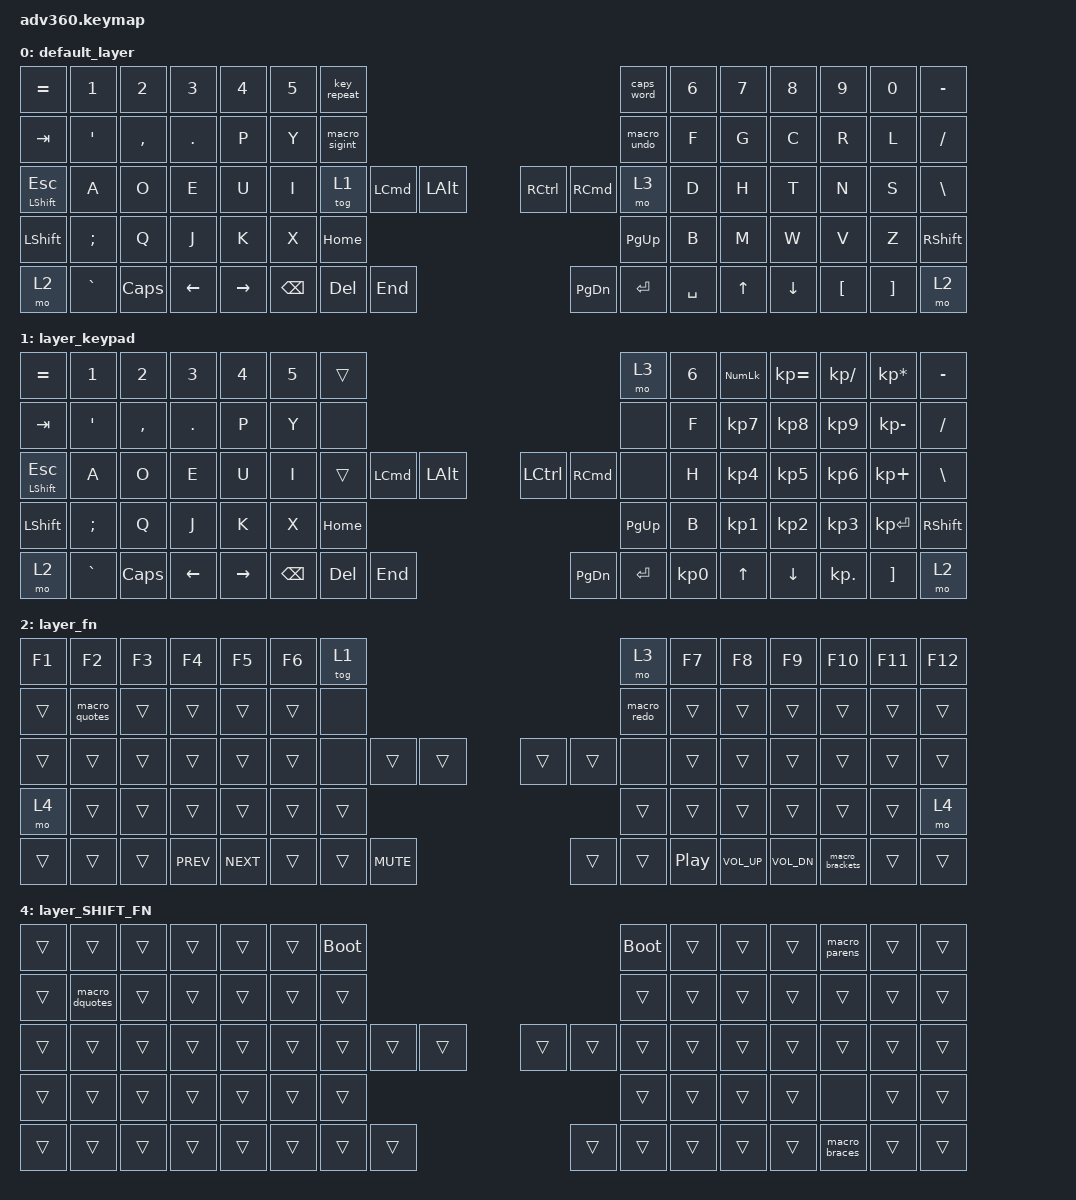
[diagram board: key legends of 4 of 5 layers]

/*
 * Copyright (c) 2020 The ZMK Contributors
 *
 * SPDX-License-Identifier: MIT
 */


/* THIS FILE WAS GENERATED!
 *
 * This file was generated automatically. You may or may not want to
 * edit it directly.
 */

#include <behaviors.dtsi>
#include <dt-bindings/zmk/keys.h>
#include <dt-bindings/zmk/bt.h>
#include <dt-bindings/zmk/rgb.h>
#include <dt-bindings/zmk/backlight.h>

/ {
  behaviors {
    #include "macros.dtsi"

    hm: homerow_mods {
        compatible = "zmk,behavior-hold-tap";
        label = "HOMEROW_MODS";
        #binding-cells = <2>;
        tapping-term-ms = <200>;
        quick_tap_ms = <175>;
        flavor = "tap-preferred";
        bindings = <&kp>, <&kp>;
    };
  };

    keymap {
        compatible = "zmk,keymap";


        default_layer {
            bindings = <
         &kp EQUAL     &kp N1     &kp N2    &kp N3     &kp N4  &kp N5              &key_repeat                                                                                     &caps_word  &kp N6  &kp N7    &kp N8    &kp N9    &kp N0  &kp MINUS
           &kp TAB    &kp SQT  &kp COMMA   &kp DOT      &kp P   &kp Y            &macro_sigint                                                                                    &macro_undo   &kp F   &kp G     &kp C     &kp R     &kp L   &kp FSLH
 &mt LSHIFT ESCAPE      &kp A      &kp O     &kp E      &kp U   &kp I                   &tog 1  &kp LEFT_COMMAND  &kp LALT                  &kp RIGHT_CONTROL  &kp RIGHT_COMMAND        &mo 3   &kp D   &kp H     &kp T     &kp N     &kp S   &kp BSLH
         &kp LSHFT   &kp SEMI      &kp Q     &kp J      &kp K   &kp X                                             &kp HOME                          &kp PG_UP                                   &kp B   &kp M     &kp W     &kp V     &kp Z  &kp RSHFT
             &mo 2  &kp GRAVE   &kp CAPS  &kp LEFT  &kp RIGHT                         &kp BSPC           &kp DEL   &kp END                          &kp PG_DN          &kp ENTER    &kp SPACE          &kp UP  &kp DOWN  &kp LBKT  &kp RBKT      &mo 2
            >;
        };

        layer_keypad {
            bindings = <
         &kp EQUAL            &kp N1     &kp N2    &kp N3     &kp N4  &kp N5              &trans                                                                                       &mo 3  &kp N6  &kp KP_NUM  &kp KP_EQUAL  &kp KP_DIVIDE  &kp KP_MULTIPLY  &kp MINUS
           &kp TAB  &kp SINGLE_QUOTE  &kp COMMA   &kp DOT      &kp P   &kp Y               &none                                                                                       &none   &kp F   &kp KP_N7     &kp KP_N8      &kp KP_N9     &kp KP_MINUS   &kp FSLH
 &mt LSHIFT ESCAPE             &kp A      &kp O     &kp E      &kp U   &kp I              &trans  &kp LEFT_COMMAND  &kp LALT                  &kp LEFT_CONTROL  &kp RIGHT_COMMAND      &none   &kp H   &kp KP_N4     &kp KP_N5      &kp KP_N6      &kp KP_PLUS   &kp BSLH
         &kp LSHFT     &kp SEMICOLON      &kp Q     &kp J      &kp K   &kp X                                        &kp HOME                         &kp PG_UP                                 &kp B   &kp KP_N1     &kp KP_N2      &kp KP_N3     &kp KP_ENTER  &kp RSHFT
             &mo 2         &kp GRAVE   &kp CAPS  &kp LEFT  &kp RIGHT                    &kp BSPC           &kp DEL   &kp END                         &kp PG_DN          &kp ENTER  &kp KP_N0              &kp UP      &kp DOWN     &kp KP_DOT         &kp RBKT      &mo 2
            >;
        };

        layer_fn {
            bindings = <
 &kp F1         &kp F2  &kp F3      &kp F4      &kp F5  &kp F6            &tog 1                                                                 &mo 3  &kp F7           &kp F8        &kp F9          &kp F10  &kp F11  &kp F12
 &trans  &macro_quotes  &trans      &trans      &trans  &trans             &none                                                           &macro_redo  &trans           &trans        &trans           &trans   &trans   &trans
 &trans         &trans  &trans      &trans      &trans  &trans             &none  &trans      &trans                  &trans  &trans             &none  &trans           &trans        &trans           &trans   &trans   &trans
  &mo 4         &trans  &trans      &trans      &trans  &trans                                &trans                  &trans                            &trans           &trans        &trans           &trans   &trans    &mo 4
 &trans         &trans  &trans  &kp C_PREV  &kp C_NEXT                    &trans  &trans  &kp C_MUTE                  &trans  &trans  &kp C_PLAY_PAUSE          &kp C_VOLUME_UP  &kp C_VOL_DN  &macro_brackets   &trans   &trans
            >;
        };

        layer_mod {
            bindings = <
  &none  &bt BT_SEL 0  &bt BT_SEL 1  &bt BT_SEL 2  &bt BT_SEL 3  &bt BT_SEL 4            &none                                                                         &none   &none       &none       &none   &none   &none   &none
  &none         &none         &none         &none         &none         &none            &none                                                          &rgb_ug RGB_MEFS_CMD   &none       &none       &none   &none   &none   &none
  &none         &none         &none         &none         &none         &none            &none   &none   &none                  &bt BT_CLR       &none                 &none   &none       &none       &none   &none   &none   &none
  &none         &none         &none         &none         &none         &none                            &none                       &none                                     &none       &none       &none   &none   &none   &none
  &none         &none         &none         &none         &none                          &none   &none   &none                       &none  &none &bl BL_TOG       &rgb_ug RGB_TOG          &bl BL_INC  &bl BL_DEC   &none   &none   &none
            >;
        };

        layer_SHIFT_FN {
            bindings = <
 &trans          &trans  &trans  &trans  &trans  &trans            &bootloader                                                  &bootloader  &trans  &trans  &trans  &macro_parens  &trans  &trans
 &trans  &macro_dquotes  &trans  &trans  &trans  &trans                 &trans                                                       &trans  &trans  &trans  &trans         &trans  &trans  &trans
 &trans          &trans  &trans  &trans  &trans  &trans                 &trans  &trans  &trans                  &trans  &trans       &trans  &trans  &trans  &trans         &trans  &trans  &trans
 &trans          &trans  &trans  &trans  &trans  &trans                                 &trans                  &trans                       &trans  &trans  &trans          &none  &trans  &trans
 &trans          &trans  &trans  &trans  &trans                         &trans  &trans  &trans                  &trans  &trans       &trans          &trans  &trans  &macro_braces  &trans  &trans
            >;
        };

    };
};
